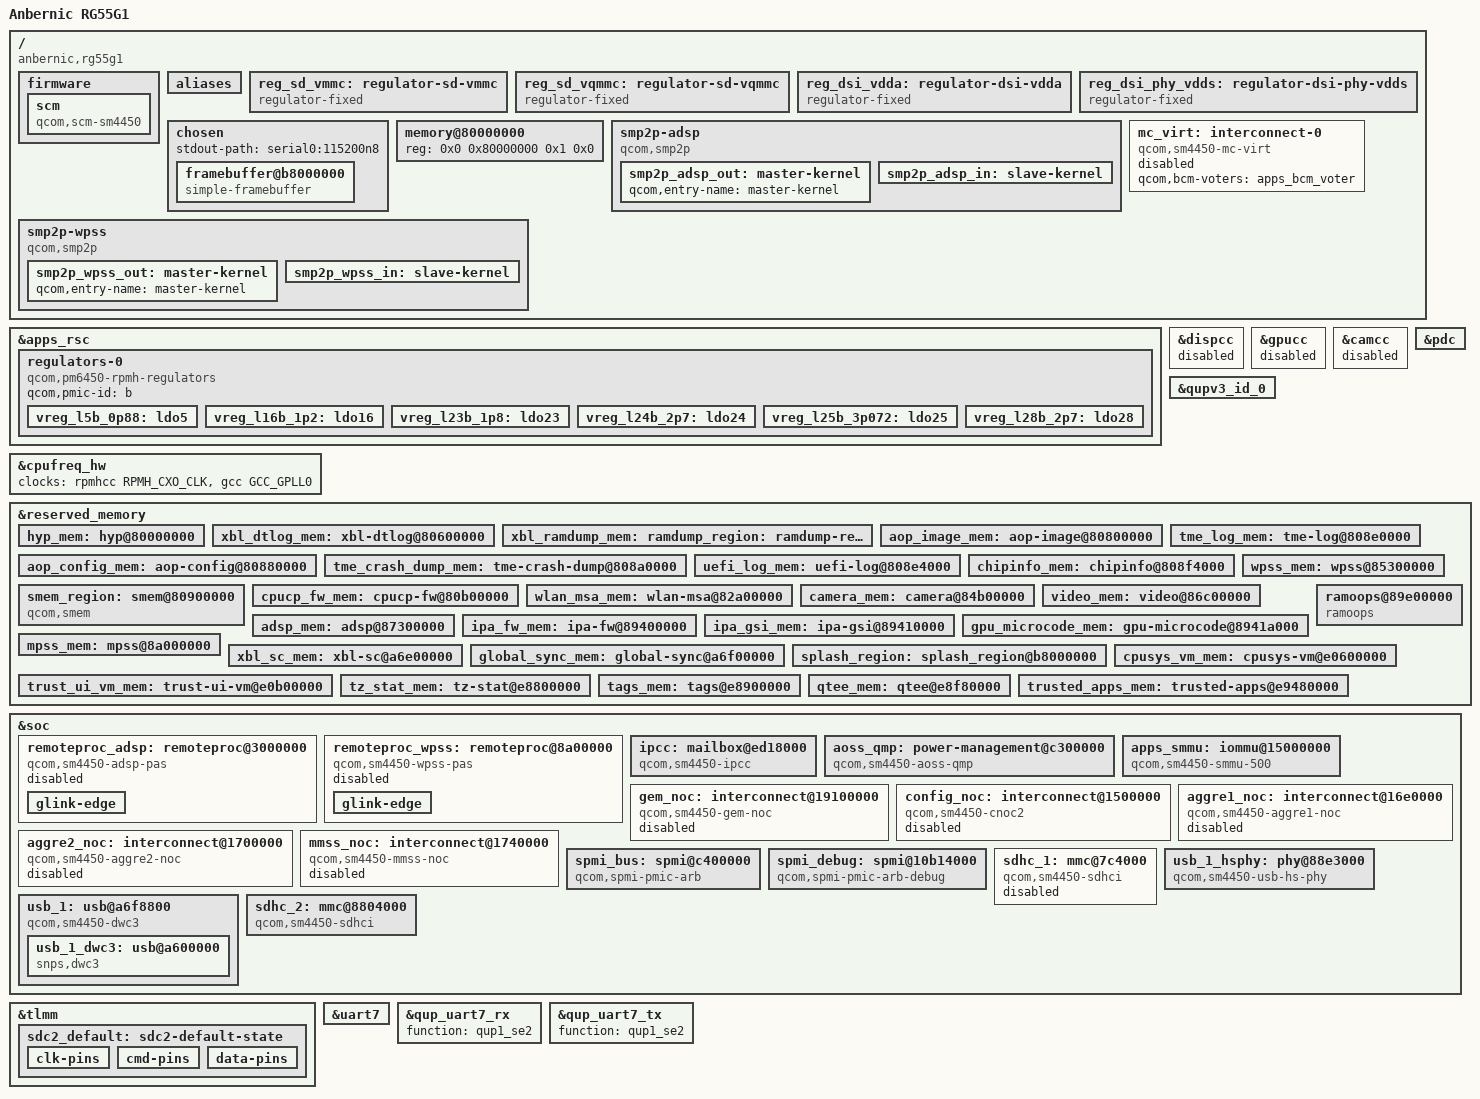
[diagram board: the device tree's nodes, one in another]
// SPDX-License-Identifier: BSD-3-Clause
/*
 * Anbernic RG55G1 (SG4250P / SM4450 "Ravelin")
 *
 * Mainline-style board DT based on sm4450.dtsi
 * By LualiLiu, with RG55G1
 * hardware (FT7131M panel, singleadc-joypad, SD slot, USB HS host/charge).
 *
 */

/dts-v1/;

#include <dt-bindings/clock/qcom,dsi-phy-28nm.h>
#include <dt-bindings/gpio/gpio.h>
#include <dt-bindings/input/linux-event-codes.h>
#include <dt-bindings/interconnect/qcom,icc.h>
#include <dt-bindings/interconnect/qcom,sm4450-rpmh.h>
#include <dt-bindings/mailbox/qcom-ipcc.h>
#include <dt-bindings/regulator/qcom,rpmh-regulator.h>
#include "sm4450.dtsi"
#include "sg4250p-anbernic-rg55g1-display.dtsi"
#include "sg4250p-anbernic-rg55g1-gpu.dtsi"
#include "sg4250p-anbernic-rg55g1-joypad.dtsi"

/ {
	model = "Anbernic RG55G1";
	compatible = "anbernic,rg55g1", "qcom,sm4450";
	chassis-type = "handset";
	qcom,msm-id = <0x28e 0x10000>, <0x238 0x10000>, <0x25a 0x10000>;
	qcom,board-id = <0x1000b 0>;

	firmware {
		scm {
			compatible = "qcom,scm-sm4450", "qcom,scm";
		};
	};

	aliases {
		serial0 = &uart7;
		mmc1 = &sdhc_2;
	};

	/*
	 * SD rails left on by ABL / raw RPMh vote. Fixed regulators avoid
	 * rpmh_regulator timeouts. Map to SDHCI-legal VDD bits:
	 *   vmmc 3.0V → POWER_300, vqmmc 1.8V → POWER_180 (stock L28B).
	 */
	reg_sd_vmmc: regulator-sd-vmmc {
		compatible = "regulator-fixed";
		regulator-name = "sd-vmmc-fixed";
		regulator-min-microvolt = <3000000>;
		regulator-max-microvolt = <3000000>;
		regulator-always-on;
		regulator-boot-on;
	};

	reg_sd_vqmmc: regulator-sd-vqmmc {
		compatible = "regulator-fixed";
		regulator-name = "sd-vqmmc-fixed";
		regulator-min-microvolt = <1800000>;
		regulator-max-microvolt = <1800000>;
		regulator-always-on;
		regulator-boot-on;
	};

	/*
	 * DSI host/PHY rails already left on by ABL. RPMh LDO enable times
	 * out on this board (same class of failure as SD rails) — use fixed
	 * always-on stubs so msm_dsi power_on can proceed after INTF quiesce.
	 */
	reg_dsi_vdda: regulator-dsi-vdda {
		compatible = "regulator-fixed";
		regulator-name = "dsi-vdda-fixed";
		regulator-min-microvolt = <1200000>;
		regulator-max-microvolt = <1200000>;
		regulator-always-on;
		regulator-boot-on;
	};

	reg_dsi_phy_vdds: regulator-dsi-phy-vdds {
		compatible = "regulator-fixed";
		regulator-name = "dsi-phy-vdds-fixed";
		regulator-min-microvolt = <880000>;
		regulator-max-microvolt = <880000>;
		regulator-always-on;
		regulator-boot-on;
	};

	chosen {
		#address-cells = <2>;
		#size-cells = <2>;
		ranges;
		stdout-path = "serial0:115200n8";

		/* ABL continuous splash → simpledrm / rg55g1_splash until MSM KMS */
		framebuffer@b8000000 {
			compatible = "simple-framebuffer";
			reg = <0x0 0xb8000000 0x0 0x7e9000>;
			width = <1080>;
			height = <1920>;
			stride = <4320>;
			format = "x8r8g8b8";
			status = "okay";
		};
	};

	/*
	 * Bootloader fills size; keep a non-zero base so mainline bootmem
	 * sees DRAM when ABL passes an incomplete /memory.
	 */
	/delete-node/ memory@a0000000;

	memory@80000000 {
		device_type = "memory";
		reg = <0x0 0x80000000 0x1 0x0>;
	};

	smp2p-adsp {
		compatible = "qcom,smp2p";
		qcom,smem = <443>, <429>;
		interrupts-extended = <&ipcc IPCC_CLIENT_LPASS
					     IPCC_MPROC_SIGNAL_SMP2P
					     IRQ_TYPE_EDGE_RISING>;
		mboxes = <&ipcc IPCC_CLIENT_LPASS IPCC_MPROC_SIGNAL_SMP2P>;
		qcom,local-pid = <0>;
		qcom,remote-pid = <2>;

		smp2p_adsp_out: master-kernel {
			qcom,entry-name = "master-kernel";
			#qcom,smem-state-cells = <1>;
		};

		smp2p_adsp_in: slave-kernel {
			qcom,entry-name = "slave-kernel";
			interrupt-controller;
			#interrupt-cells = <2>;
		};
	};

	smp2p-wpss {
		compatible = "qcom,smp2p";
		qcom,smem = <617>, <616>;
		interrupts-extended = <&ipcc IPCC_CLIENT_WPSS
					     IPCC_MPROC_SIGNAL_SMP2P
					     IRQ_TYPE_EDGE_RISING>;
		mboxes = <&ipcc IPCC_CLIENT_WPSS IPCC_MPROC_SIGNAL_SMP2P>;
		qcom,local-pid = <0>;
		qcom,remote-pid = <13>;

		smp2p_wpss_out: master-kernel {
			qcom,entry-name = "master-kernel";
			#qcom,smem-state-cells = <1>;
		};

		smp2p_wpss_in: slave-kernel {
			qcom,entry-name = "slave-kernel";
			interrupt-controller;
			#interrupt-cells = <2>;
		};
	};

	mc_virt: interconnect-0 {
		compatible = "qcom,sm4450-mc-virt";
		#interconnect-cells = <2>;
		qcom,bcm-voters = <&apps_bcm_voter>;
		/* RPMh AMC not ready at probe → rpmh_write_batch WARN -110 */
		status = "disabled";
	};
};

&apps_rsc {
	regulators-0 {
		compatible = "qcom,pm6450-rpmh-regulators";
		qcom,pmic-id = "b";

		vreg_l5b_0p88: ldo5 {
			regulator-name = "vreg_l5b_0p88";
			regulator-min-microvolt = <312000>;
			regulator-max-microvolt = <1052000>;
			regulator-initial-mode = <RPMH_REGULATOR_MODE_HPM>;
		};

		vreg_l16b_1p2: ldo16 {
			regulator-name = "vreg_l16b_1p2";
			regulator-min-microvolt = <312000>;
			regulator-max-microvolt = <1260000>;
			regulator-initial-mode = <RPMH_REGULATOR_MODE_HPM>;
		};

		vreg_l23b_1p8: ldo23 {
			regulator-name = "vreg_l23b_1p8";
			regulator-min-microvolt = <1620000>;
			regulator-max-microvolt = <1980000>;
			regulator-initial-mode = <RPMH_REGULATOR_MODE_HPM>;
		};

		vreg_l24b_2p7: ldo24 {
			regulator-name = "vreg_l24b_2p7";
			regulator-min-microvolt = <2700000>;
			regulator-max-microvolt = <3544000>;
			regulator-initial-mode = <RPMH_REGULATOR_MODE_HPM>;
		};

		vreg_l25b_3p072: ldo25 {
			regulator-name = "vreg_l25b_3p072";
			regulator-min-microvolt = <2700000>;
			regulator-max-microvolt = <3544000>;
			regulator-initial-mode = <RPMH_REGULATOR_MODE_HPM>;
		};

		vreg_l28b_2p7: ldo28 {
			regulator-name = "vreg_l28b_2p7";
			regulator-min-microvolt = <1620000>;
			regulator-max-microvolt = <3300000>;
			regulator-initial-mode = <RPMH_REGULATOR_MODE_HPM>;
		};
	};
};

&cpufreq_hw {
	clocks = <&rpmhcc RPMH_CXO_CLK>, <&gcc GCC_GPLL0>;
};

&dispcc {
	clocks = <&rpmhcc RPMH_CXO_CLK>,
		 <&rpmhcc RPMH_CXO_CLK_A>,
		 <&gcc GCC_DISP_AHB_CLK>,
		 <&sleep_clk>,
		 <&mdss_dsi0_phy DSI_BYTE_PLL_CLK>,
		 <&mdss_dsi0_phy DSI_PIXEL_PLL_CLK>;
	/*
	 * No rpmhpd: ABL already voted MX for splash; rpmh_write times out
	 * (-ETIMEDOUT / WARN) and stalls MSM handoff for 10s+ per rail.
	 */
	/* Probe only via rg55g1 MSM handoff — early OF probe kills ABL splash. */
	status = "disabled";
};

&gpucc {
	/*
	 * No rpmhpd CX/MX — same RPMh AMC timeout as dispcc. GDSCs inside
	 * GPUCC still manage GX/CX locally for Adreno.
	 */
	status = "disabled";
};

&camcc {
	status = "disabled";
};

&pdc {
	reg = <0x0 0x0b220000 0x0 0x10000>, <0x0 0x174000f0 0x0 0x64>;
};

&qupv3_id_0 {
	status = "okay";
};

&reserved_memory {
	hyp_mem: hyp@80000000 {
		reg = <0x0 0x80000000 0x0 0x600000>;
		no-map;
	};

	xbl_dtlog_mem: xbl-dtlog@80600000 {
		reg = <0x0 0x80600000 0x0 0x40000>;
		no-map;
	};

	/* rocknix-abl looks up "ramdump-region"; also keep xbl label */
	xbl_ramdump_mem: ramdump_region: ramdump-region@80640000 {
		reg = <0x0 0x80640000 0x0 0x1c0000>;
		no-map;
	};

	aop_image_mem: aop-image@80800000 {
		reg = <0x0 0x80800000 0x0 0x60000>;
		no-map;
	};

	aop_config_mem: aop-config@80880000 {
		reg = <0x0 0x80880000 0x0 0x20000>;
		no-map;
	};

	tme_crash_dump_mem: tme-crash-dump@808a0000 {
		reg = <0x0 0x808a0000 0x0 0x40000>;
		no-map;
	};

	tme_log_mem: tme-log@808e0000 {
		reg = <0x0 0x808e0000 0x0 0x4000>;
		no-map;
	};

	uefi_log_mem: uefi-log@808e4000 {
		reg = <0x0 0x808e4000 0x0 0x10000>;
		no-map;
	};

	chipinfo_mem: chipinfo@808f4000 {
		reg = <0x0 0x808f4000 0x0 0x1000>;
		no-map;
	};

	smem_region: smem@80900000 {
		compatible = "qcom,smem";
		reg = <0x0 0x80900000 0x0 0x200000>;
		no-map;
		hwlocks = <&tcsr_mutex 3>;
	};

	cpucp_fw_mem: cpucp-fw@80b00000 {
		reg = <0x0 0x80b00000 0x0 0x100000>;
		no-map;
	};

	wlan_msa_mem: wlan-msa@82a00000 {
		reg = <0x0 0x82a00000 0x0 0xc00000>;
		no-map;
	};

	camera_mem: camera@84b00000 {
		reg = <0x0 0x84b00000 0x0 0x800000>;
		no-map;
	};

	wpss_mem: wpss@85300000 {
		reg = <0x0 0x85300000 0x0 0x1900000>;
		no-map;
	};

	video_mem: video@86c00000 {
		reg = <0x0 0x86c00000 0x0 0x700000>;
		no-map;
	};

	adsp_mem: adsp@87300000 {
		reg = <0x0 0x87300000 0x0 0x2100000>;
		no-map;
	};

	ipa_fw_mem: ipa-fw@89400000 {
		reg = <0x0 0x89400000 0x0 0x10000>;
		no-map;
	};

	ipa_gsi_mem: ipa-gsi@89410000 {
		reg = <0x0 0x89410000 0x0 0xa000>;
		no-map;
	};

	gpu_microcode_mem: gpu-microcode@8941a000 {
		reg = <0x0 0x8941a000 0x0 0x2000>;
		no-map;
	};

	ramoops@89e00000 {
		compatible = "ramoops";
		reg = <0x0 0x89e00000 0x0 0x200000>;
		console-size = <0x100000>;
		record-size = <0x20000>;
		pmsg-size = <0x20000>;
	};

	mpss_mem: mpss@8a000000 {
		reg = <0x0 0x8a000000 0x0 0xda00000>;
		no-map;
	};

	xbl_sc_mem: xbl-sc@a6e00000 {
		reg = <0x0 0xa6e00000 0x0 0x40000>;
		no-map;
	};

	global_sync_mem: global-sync@a6f00000 {
		reg = <0x0 0xa6f00000 0x0 0x100000>;
		no-map;
	};

	splash_region: splash_region@b8000000 {
		reg = <0x0 0xb8000000 0x0 0x2b00000>;
		no-map;
	};

	cpusys_vm_mem: cpusys-vm@e0600000 {
		reg = <0x0 0xe0600000 0x0 0x400000>;
		no-map;
	};

	trust_ui_vm_mem: trust-ui-vm@e0b00000 {
		reg = <0x0 0xe0b00000 0x0 0x4af3000>;
		no-map;
	};

	tz_stat_mem: tz-stat@e8800000 {
		reg = <0x0 0xe8800000 0x0 0x100000>;
		no-map;
	};

	tags_mem: tags@e8900000 {
		reg = <0x0 0xe8900000 0x0 0x680000>;
		no-map;
	};

	qtee_mem: qtee@e8f80000 {
		reg = <0x0 0xe8f80000 0x0 0x500000>;
		no-map;
	};

	trusted_apps_mem: trusted-apps@e9480000 {
		reg = <0x0 0xe9480000 0x0 0x1200000>;
		no-map;
	};
};

&soc {
	remoteproc_adsp: remoteproc@3000000 {
		compatible = "qcom,sm4450-adsp-pas";
		reg = <0x0 0x03000000 0x0 0x10000>;

		interrupts-extended = <&pdc 6 IRQ_TYPE_EDGE_RISING>,
				      <&smp2p_adsp_in 0 IRQ_TYPE_EDGE_RISING>,
				      <&smp2p_adsp_in 1 IRQ_TYPE_EDGE_RISING>,
				      <&smp2p_adsp_in 2 IRQ_TYPE_EDGE_RISING>,
				      <&smp2p_adsp_in 3 IRQ_TYPE_EDGE_RISING>;
		interrupt-names = "wdog", "fatal", "ready",
				  "handover", "stop-ack";

		clocks = <&rpmhcc RPMH_CXO_CLK>;
		clock-names = "xo";

		power-domains = <&rpmhpd RPMHPD_LCX>,
				<&rpmhpd RPMHPD_LMX>;
		power-domain-names = "lcx", "lmx";

		memory-region = <&adsp_mem>;

		qcom,qmp = <&aoss_qmp>;
		qcom,smem-states = <&smp2p_adsp_out 0>;
		qcom,smem-state-names = "stop";

		firmware-name = "qcom/sm4450/adsp.mbn";
		status = "disabled";

		glink-edge {
			interrupts-extended = <&ipcc IPCC_CLIENT_LPASS
						     IPCC_MPROC_SIGNAL_GLINK_QMP
						     IRQ_TYPE_EDGE_RISING>;
			mboxes = <&ipcc IPCC_CLIENT_LPASS
					IPCC_MPROC_SIGNAL_GLINK_QMP>;
			label = "lpass";
			qcom,remote-pid = <2>;
		};
	};

	remoteproc_wpss: remoteproc@8a00000 {
		compatible = "qcom,sm4450-wpss-pas";
		reg = <0x0 0x08a00000 0x0 0x10000>;

		interrupts-extended = <&intc GIC_SPI 587 IRQ_TYPE_EDGE_RISING>,
				      <&smp2p_wpss_in 0 IRQ_TYPE_EDGE_RISING>,
				      <&smp2p_wpss_in 1 IRQ_TYPE_EDGE_RISING>,
				      <&smp2p_wpss_in 2 IRQ_TYPE_EDGE_RISING>,
				      <&smp2p_wpss_in 3 IRQ_TYPE_EDGE_RISING>;
		interrupt-names = "wdog", "fatal", "ready",
				  "handover", "stop-ack";

		clocks = <&rpmhcc RPMH_CXO_CLK>;
		clock-names = "xo";

		power-domains = <&rpmhpd RPMHPD_CX>,
				<&rpmhpd RPMHPD_MX>;
		power-domain-names = "cx", "mx";

		memory-region = <&wpss_mem>;

		qcom,qmp = <&aoss_qmp>;
		qcom,smem-states = <&smp2p_wpss_out 0>;
		qcom,smem-state-names = "stop";

		firmware-name = "qcom/sm4450/wpss.mbn";
		status = "disabled";

		glink-edge {
			interrupts-extended = <&ipcc IPCC_CLIENT_WPSS
						     IPCC_MPROC_SIGNAL_GLINK_QMP
						     IRQ_TYPE_EDGE_RISING>;
			mboxes = <&ipcc IPCC_CLIENT_WPSS
					IPCC_MPROC_SIGNAL_GLINK_QMP>;
			label = "wpss";
			qcom,remote-pid = <13>;
		};
	};

	ipcc: mailbox@ed18000 {
		compatible = "qcom,sm4450-ipcc", "qcom,ipcc";
		reg = <0x0 0x0ed18000 0x0 0x1000>;
		interrupts = <GIC_SPI 229 IRQ_TYPE_LEVEL_HIGH>;
		interrupt-controller;
		#interrupt-cells = <3>;
		#mbox-cells = <2>;
	};

	aoss_qmp: power-management@c300000 {
		compatible = "qcom,sm4450-aoss-qmp", "qcom,aoss-qmp";
		reg = <0x0 0x0c300000 0x0 0x400>;
		interrupts-extended = <&ipcc IPCC_CLIENT_AOP
					     IPCC_MPROC_SIGNAL_GLINK_QMP
					     IRQ_TYPE_EDGE_RISING>;
		mboxes = <&ipcc IPCC_CLIENT_AOP IPCC_MPROC_SIGNAL_GLINK_QMP>;
		#clock-cells = <0>;
	};

	/*
	 * Apps SMMU — SIDs used by USB (0x540), SD (0x140), MDSS (0x800).
	 * ROCKNIX keeps this enabled; display path quiesces ABL INTF in
	 * dispcc probe then attaches MDSS with a normal paging domain.
	 */
	apps_smmu: iommu@15000000 {
		compatible = "qcom,sm4450-smmu-500", "qcom,smmu-500",
			     "arm,mmu-500";
		reg = <0x0 0x15000000 0x0 0x100000>;
		#iommu-cells = <2>;
		#global-interrupts = <1>;
		dma-coherent;
		status = "okay";

		interrupts = <GIC_SPI 65 IRQ_TYPE_LEVEL_HIGH>,
			     <GIC_SPI 94 IRQ_TYPE_LEVEL_HIGH>,
			     <GIC_SPI 95 IRQ_TYPE_LEVEL_HIGH>,
			     <GIC_SPI 96 IRQ_TYPE_LEVEL_HIGH>,
			     <GIC_SPI 670 IRQ_TYPE_LEVEL_HIGH>,
			     <GIC_SPI 671 IRQ_TYPE_LEVEL_HIGH>,
			     <GIC_SPI 97 IRQ_TYPE_LEVEL_HIGH>,
			     <GIC_SPI 98 IRQ_TYPE_LEVEL_HIGH>,
			     <GIC_SPI 99 IRQ_TYPE_LEVEL_HIGH>,
			     <GIC_SPI 100 IRQ_TYPE_LEVEL_HIGH>,
			     <GIC_SPI 101 IRQ_TYPE_LEVEL_HIGH>,
			     <GIC_SPI 102 IRQ_TYPE_LEVEL_HIGH>,
			     <GIC_SPI 103 IRQ_TYPE_LEVEL_HIGH>,
			     <GIC_SPI 104 IRQ_TYPE_LEVEL_HIGH>,
			     <GIC_SPI 105 IRQ_TYPE_LEVEL_HIGH>,
			     <GIC_SPI 106 IRQ_TYPE_LEVEL_HIGH>,
			     <GIC_SPI 107 IRQ_TYPE_LEVEL_HIGH>,
			     <GIC_SPI 108 IRQ_TYPE_LEVEL_HIGH>,
			     <GIC_SPI 109 IRQ_TYPE_LEVEL_HIGH>,
			     <GIC_SPI 110 IRQ_TYPE_LEVEL_HIGH>,
			     <GIC_SPI 111 IRQ_TYPE_LEVEL_HIGH>,
			     <GIC_SPI 112 IRQ_TYPE_LEVEL_HIGH>,
			     <GIC_SPI 113 IRQ_TYPE_LEVEL_HIGH>,
			     <GIC_SPI 114 IRQ_TYPE_LEVEL_HIGH>,
			     <GIC_SPI 115 IRQ_TYPE_LEVEL_HIGH>,
			     <GIC_SPI 116 IRQ_TYPE_LEVEL_HIGH>,
			     <GIC_SPI 117 IRQ_TYPE_LEVEL_HIGH>,
			     <GIC_SPI 118 IRQ_TYPE_LEVEL_HIGH>,
			     <GIC_SPI 181 IRQ_TYPE_LEVEL_HIGH>,
			     <GIC_SPI 182 IRQ_TYPE_LEVEL_HIGH>,
			     <GIC_SPI 183 IRQ_TYPE_LEVEL_HIGH>,
			     <GIC_SPI 184 IRQ_TYPE_LEVEL_HIGH>,
			     <GIC_SPI 185 IRQ_TYPE_LEVEL_HIGH>,
			     <GIC_SPI 186 IRQ_TYPE_LEVEL_HIGH>,
			     <GIC_SPI 187 IRQ_TYPE_LEVEL_HIGH>,
			     <GIC_SPI 188 IRQ_TYPE_LEVEL_HIGH>,
			     <GIC_SPI 189 IRQ_TYPE_LEVEL_HIGH>,
			     <GIC_SPI 190 IRQ_TYPE_LEVEL_HIGH>,
			     <GIC_SPI 191 IRQ_TYPE_LEVEL_HIGH>,
			     <GIC_SPI 192 IRQ_TYPE_LEVEL_HIGH>,
			     <GIC_SPI 315 IRQ_TYPE_LEVEL_HIGH>,
			     <GIC_SPI 316 IRQ_TYPE_LEVEL_HIGH>,
			     <GIC_SPI 317 IRQ_TYPE_LEVEL_HIGH>,
			     <GIC_SPI 318 IRQ_TYPE_LEVEL_HIGH>,
			     <GIC_SPI 319 IRQ_TYPE_LEVEL_HIGH>,
			     <GIC_SPI 320 IRQ_TYPE_LEVEL_HIGH>,
			     <GIC_SPI 321 IRQ_TYPE_LEVEL_HIGH>,
			     <GIC_SPI 322 IRQ_TYPE_LEVEL_HIGH>,
			     <GIC_SPI 323 IRQ_TYPE_LEVEL_HIGH>,
			     <GIC_SPI 324 IRQ_TYPE_LEVEL_HIGH>,
			     <GIC_SPI 325 IRQ_TYPE_LEVEL_HIGH>,
			     <GIC_SPI 326 IRQ_TYPE_LEVEL_HIGH>,
			     <GIC_SPI 327 IRQ_TYPE_LEVEL_HIGH>,
			     <GIC_SPI 328 IRQ_TYPE_LEVEL_HIGH>,
			     <GIC_SPI 329 IRQ_TYPE_LEVEL_HIGH>,
			     <GIC_SPI 330 IRQ_TYPE_LEVEL_HIGH>,
			     <GIC_SPI 331 IRQ_TYPE_LEVEL_HIGH>,
			     <GIC_SPI 332 IRQ_TYPE_LEVEL_HIGH>,
			     <GIC_SPI 333 IRQ_TYPE_LEVEL_HIGH>,
			     <GIC_SPI 334 IRQ_TYPE_LEVEL_HIGH>,
			     <GIC_SPI 335 IRQ_TYPE_LEVEL_HIGH>,
			     <GIC_SPI 336 IRQ_TYPE_LEVEL_HIGH>,
			     <GIC_SPI 337 IRQ_TYPE_LEVEL_HIGH>,
			     <GIC_SPI 338 IRQ_TYPE_LEVEL_HIGH>,
			     <GIC_SPI 339 IRQ_TYPE_LEVEL_HIGH>,
			     <GIC_SPI 340 IRQ_TYPE_LEVEL_HIGH>,
			     <GIC_SPI 341 IRQ_TYPE_LEVEL_HIGH>,
			     <GIC_SPI 342 IRQ_TYPE_LEVEL_HIGH>,
			     <GIC_SPI 343 IRQ_TYPE_LEVEL_HIGH>,
			     <GIC_SPI 344 IRQ_TYPE_LEVEL_HIGH>,
			     <GIC_SPI 345 IRQ_TYPE_LEVEL_HIGH>,
			     <GIC_SPI 395 IRQ_TYPE_LEVEL_HIGH>,
			     <GIC_SPI 396 IRQ_TYPE_LEVEL_HIGH>,
			     <GIC_SPI 397 IRQ_TYPE_LEVEL_HIGH>,
			     <GIC_SPI 398 IRQ_TYPE_LEVEL_HIGH>,
			     <GIC_SPI 399 IRQ_TYPE_LEVEL_HIGH>,
			     <GIC_SPI 400 IRQ_TYPE_LEVEL_HIGH>,
			     <GIC_SPI 401 IRQ_TYPE_LEVEL_HIGH>,
			     <GIC_SPI 402 IRQ_TYPE_LEVEL_HIGH>,
			     <GIC_SPI 403 IRQ_TYPE_LEVEL_HIGH>,
			     <GIC_SPI 404 IRQ_TYPE_LEVEL_HIGH>,
			     <GIC_SPI 405 IRQ_TYPE_LEVEL_HIGH>,
			     <GIC_SPI 406 IRQ_TYPE_LEVEL_HIGH>,
			     <GIC_SPI 407 IRQ_TYPE_LEVEL_HIGH>,
			     <GIC_SPI 408 IRQ_TYPE_LEVEL_HIGH>,
			     <GIC_SPI 409 IRQ_TYPE_LEVEL_HIGH>,
			     <GIC_SPI 418 IRQ_TYPE_LEVEL_HIGH>,
			     <GIC_SPI 419 IRQ_TYPE_LEVEL_HIGH>,
			     <GIC_SPI 412 IRQ_TYPE_LEVEL_HIGH>,
			     <GIC_SPI 421 IRQ_TYPE_LEVEL_HIGH>,
			     <GIC_SPI 707 IRQ_TYPE_LEVEL_HIGH>,
			     <GIC_SPI 423 IRQ_TYPE_LEVEL_HIGH>,
			     <GIC_SPI 424 IRQ_TYPE_LEVEL_HIGH>,
			     <GIC_SPI 425 IRQ_TYPE_LEVEL_HIGH>,
			     <GIC_SPI 690 IRQ_TYPE_LEVEL_HIGH>,
			     <GIC_SPI 691 IRQ_TYPE_LEVEL_HIGH>,
			     <GIC_SPI 692 IRQ_TYPE_LEVEL_HIGH>;
	};

	/* Interconnect providers — disabled until RPMh AMC/cmd-db is reliable.
	 * Early probe triggers: rpmh_write_batch WARN, "Error sending AMC RPMH (-110)".
	 */
	gem_noc: interconnect@19100000 {
		compatible = "qcom,sm4450-gem-noc";
		reg = <0x0 0x19100000 0x0 0xbc080>;
		#interconnect-cells = <2>;
		qcom,bcm-voters = <&apps_bcm_voter>;
		status = "disabled";
	};

	config_noc: interconnect@1500000 {
		compatible = "qcom,sm4450-cnoc2";
		reg = <0x0 0x01500000 0x0 0x6200>;
		#interconnect-cells = <2>;
		qcom,bcm-voters = <&apps_bcm_voter>;
		status = "disabled";
	};

	aggre1_noc: interconnect@16e0000 {
		compatible = "qcom,sm4450-aggre1-noc";
		reg = <0x0 0x016e0000 0x0 0x13080>;
		#interconnect-cells = <2>;
		qcom,bcm-voters = <&apps_bcm_voter>;
		status = "disabled";
	};

	aggre2_noc: interconnect@1700000 {
		compatible = "qcom,sm4450-aggre2-noc";
		reg = <0x0 0x01700000 0x0 0x1b080>;
		#interconnect-cells = <2>;
		qcom,bcm-voters = <&apps_bcm_voter>;
		status = "disabled";
	};

	mmss_noc: interconnect@1740000 {
		compatible = "qcom,sm4450-mmss-noc";
		reg = <0x0 0x01740000 0x0 0x19080>;
		#interconnect-cells = <2>;
		qcom,bcm-voters = <&apps_bcm_voter>;
		status = "disabled";
	};

	/*
	 * SPMI PMIC arbiter — required for PM7250B OTG/VBUS (USB-HOST).
	 * Debug arb bypasses EE ownership so HLOS can write charger/Type-C.
	 */
	spmi_bus: spmi@c400000 {
		compatible = "qcom,spmi-pmic-arb";
		reg = <0x0 0x0c400000 0x0 0x3000>,
		      <0x0 0x0c500000 0x0 0x400000>,
		      <0x0 0x0c440000 0x0 0x80000>,
		      <0x0 0x0c4c0000 0x0 0x10000>,
		      <0x0 0x0c42d000 0x0 0x4000>;
		reg-names = "core", "chnls", "obsrvr", "intr", "cnfg";
		interrupt-names = "periph_irq";
		interrupts-extended = <&pdc 1 IRQ_TYPE_LEVEL_HIGH>;
		qcom,ee = <0>;
		qcom,channel = <0>;
		#address-cells = <2>;
		#size-cells = <0>;
		interrupt-controller;
		#interrupt-cells = <4>;
		status = "okay";
	};

	spmi_debug: spmi@10b14000 {
		compatible = "qcom,spmi-pmic-arb-debug";
		reg = <0x0 0x10b14000 0x0 0x60>,
		      <0x0 0x221c8784 0x0 0x4>;
		reg-names = "core", "fuse";
		clocks = <&aoss_qmp>;
		clock-names = "core_clk";
		qcom,fuse-enable-bit = <18>;
		#address-cells = <2>;
		#size-cells = <0>;
		status = "okay";
	};

	/* eMMC (SDC1) — not populated on RG55G1 */
	sdhc_1: mmc@7c4000 {
		compatible = "qcom,sm4450-sdhci", "qcom,sdhci-msm-v5";
		reg = <0x0 0x007c4000 0x0 0x1000>,
		      <0x0 0x007c5000 0x0 0x1000>;
		reg-names = "hc", "cqhci";
		interrupts = <GIC_SPI 135 IRQ_TYPE_LEVEL_HIGH>,
			     <GIC_SPI 137 IRQ_TYPE_LEVEL_HIGH>;
		interrupt-names = "hc_irq", "pwr_irq";
		clocks = <&gcc GCC_SDCC1_AHB_CLK>,
			 <&gcc GCC_SDCC1_APPS_CLK>,
			 <&rpmhcc RPMH_CXO_CLK>;
		clock-names = "iface", "core", "xo";
		power-domains = <&rpmhpd RPMHPD_CX>;
		bus-width = <8>;
		supports-cqe;
		non-removable;
		status = "disabled";
	};

	usb_1_hsphy: phy@88e3000 {
		compatible = "qcom,sm4450-usb-hs-phy",
			     "qcom,usb-snps-hs-7nm-phy";
		reg = <0x0 0x088e3000 0x0 0x120>;
		#phy-cells = <0>;
		clocks = <&rpmhcc RPMH_CXO_CLK>;
		clock-names = "ref";
		resets = <&gcc GCC_QUSB2PHY_PRIM_BCR>;
		vdda-pll-supply = <&vreg_l5b_0p88>;
		vdda18-supply = <&vreg_l23b_1p8>;
		vdda33-supply = <&vreg_l25b_3p072>;
		status = "okay";
	};

	/*
	 * USB3 DWC3 glue + core (legacy nested layout for dwc3-qcom-legacy).
	 * HS-only: host for OTG keyboard, peripheral for USB charge/gadget.
	 */
	usb_1: usb@a6f8800 {
		compatible = "qcom,sm4450-dwc3", "qcom,dwc3";
		reg = <0x0 0x0a6f8800 0x0 0x400>;
		#address-cells = <2>;
		#size-cells = <2>;
		ranges;
		status = "okay";

		clocks = <&gcc GCC_CFG_NOC_USB3_PRIM_AXI_CLK>,
			 <&gcc GCC_USB30_PRIM_MASTER_CLK>,
			 <&gcc GCC_AGGRE_USB3_PRIM_AXI_CLK>,
			 <&gcc GCC_USB30_PRIM_SLEEP_CLK>,
			 <&gcc GCC_USB30_PRIM_MOCK_UTMI_CLK>;
		clock-names = "cfg_noc",
			      "core",
			      "iface",
			      "sleep",
			      "mock_utmi";

		assigned-clocks = <&gcc GCC_USB30_PRIM_MOCK_UTMI_CLK>,
				  <&gcc GCC_USB30_PRIM_MASTER_CLK>;
		assigned-clock-rates = <19200000>, <133333333>;

		interrupts-extended = <&intc GIC_SPI 130 IRQ_TYPE_LEVEL_HIGH>,
				      <&pdc 14 IRQ_TYPE_EDGE_BOTH>,
				      <&pdc 15 IRQ_TYPE_EDGE_BOTH>,
				      <&pdc 17 IRQ_TYPE_LEVEL_HIGH>;
		interrupt-names = "pwr_event",
				  "dp_hs_phy_irq",
				  "dm_hs_phy_irq",
				  "ss_phy_irq";

		power-domains = <&gcc GCC_USB30_PRIM_GDSC>;
		resets = <&gcc GCC_USB30_PRIM_BCR>;
		qcom,select-utmi-as-pipe-clk;

		usb_1_dwc3: usb@a600000 {
			compatible = "snps,dwc3";
			reg = <0x0 0x0a600000 0x0 0xd800>;
			interrupts = <GIC_SPI 133 IRQ_TYPE_LEVEL_HIGH>;
			iommus = <&apps_smmu 0x540 0x0>;
			snps,dis_u2_susphy_quirk;
			snps,dis_enblslpm_quirk;
			phys = <&usb_1_hsphy>;
			phy-names = "usb2-phy";
			maximum-speed = "high-speed";
			dr_mode = "otg";
			usb-role-switch;
			role-switch-default-mode = "host";
		};
	};

	/* SD card slot (SDC2) */
	sdhc_2: mmc@8804000 {
		compatible = "qcom,sm4450-sdhci", "qcom,sdhci-msm-v5";
		reg = <0x0 0x08804000 0x0 0x1000>;
		reg-names = "hc";
		interrupts = <GIC_SPI 207 IRQ_TYPE_LEVEL_HIGH>,
			     <GIC_SPI 223 IRQ_TYPE_LEVEL_HIGH>;
		interrupt-names = "hc_irq", "pwr_irq";
		clocks = <&gcc GCC_SDCC2_AHB_CLK>,
			 <&gcc GCC_SDCC2_APPS_CLK>,
			 <&rpmhcc RPMH_CXO_CLK>;
		clock-names = "iface", "core", "xo";
		/* No iommus — SMMU bypass; force PIO (avoids ADMA + runtime PM hang). */
		qcom,force-pio;
		pinctrl-0 = <&sdc2_default>;
		pinctrl-names = "default";
		vmmc-supply = <&reg_sd_vmmc>;
		vqmmc-supply = <&reg_sd_vqmmc>;
		bus-width = <4>;
		max-frequency = <25000000>;
		cd-gpios = <&tlmm 101 GPIO_ACTIVE_LOW>;
		no-sdio;
		no-mmc;
		status = "okay";
	};
};

&tlmm {
	sdc2_default: sdc2-default-state {
		clk-pins {
			pins = "sdc2_clk";
			drive-strength = <16>;
			bias-disable;
		};

		cmd-pins {
			pins = "sdc2_cmd";
			drive-strength = <10>;
			bias-pull-up;
		};

		data-pins {
			pins = "sdc2_data";
			drive-strength = <10>;
			bias-pull-up;
		};
	};
};

&uart7 {
	status = "okay";
};

/* sm4450 TLMM only has mux "qup1_se2" (not qup1_se2_l2 from other SoCs). */
&qup_uart7_rx {
	function = "qup1_se2";
};

&qup_uart7_tx {
	function = "qup1_se2";
};
